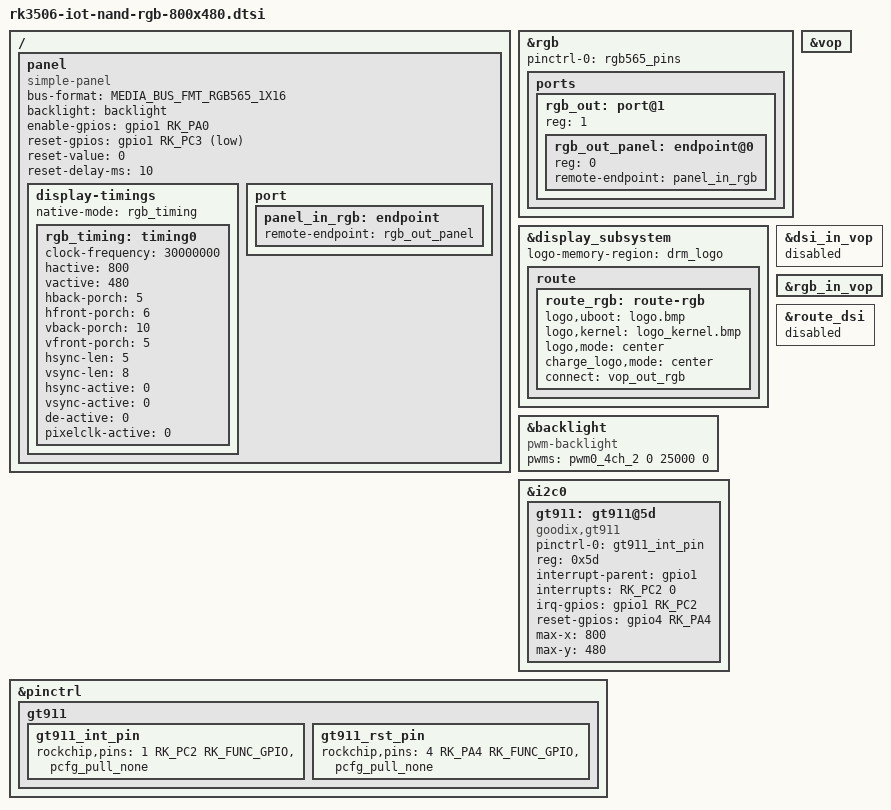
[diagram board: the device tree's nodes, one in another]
// SPDX-License-Identifier: (GPL-2.0+ OR MIT)
/*
 * Copyright (c) 2024 Rockchip Electronics Co., Ltd.
 */

#include <dt-bindings/display/media-bus-format.h>

/ {
	panel: panel {
		compatible = "simple-panel";
		bus-format = <MEDIA_BUS_FMT_RGB565_1X16>;
		backlight = <&backlight>;
		enable-gpios = <&gpio1 RK_PA0 GPIO_ACTIVE_HIGH>;
		//enable-delay-ms = <20>;
		reset-gpios = <&gpio1 RK_PC3 GPIO_ACTIVE_LOW>;
		reset-value = <0>;
		reset-delay-ms = <10>;
		status = "okay";

		display-timings {
			native-mode = <&rgb_timing>;

			rgb_timing: timing0 {
				clock-frequency = <30000000>;
				hactive = <800>;
				vactive = <480>;
				hback-porch = <5>;
				hfront-porch = <6>;
				vback-porch = <10>;
				vfront-porch = <5>;
				hsync-len = <5>;
				vsync-len = <8>;
				hsync-active = <0>;
				vsync-active = <0>;
				de-active = <0>;
				pixelclk-active = <0>;
			};
		};

		port {
			panel_in_rgb: endpoint {
				remote-endpoint = <&rgb_out_panel>;
			};
		};
	};

};

&rgb {
	status = "okay";
	pinctrl-names = "default";
	pinctrl-0 = <&rgb565_pins>;

	ports {
		rgb_out: port@1 {
			reg = <1>;
			#address-cells = <1>;
			#size-cells = <0>;

			rgb_out_panel: endpoint@0 {
				reg = <0>;
				remote-endpoint = <&panel_in_rgb>;
			};
		};
	};
};

&display_subsystem {
	status = "okay";
	logo-memory-region = <&drm_logo>;
	route {
		route_rgb: route-rgb {
			status = "okay";
			logo,uboot = "logo.bmp";
			logo,kernel = "logo_kernel.bmp";
			logo,mode = "center";
			charge_logo,mode = "center";
			connect = <&vop_out_rgb>;
		};
	};
};

&vop {
	status = "okay";
};

&dsi_in_vop {
	status = "disabled";
};

&rgb_in_vop {
	status = "okay";
};

&route_dsi {
	status = "disabled";
};

&route_rgb {
	status = "okay";
};

&backlight {
	compatible = "pwm-backlight";
	pwms = <&pwm0_4ch_2 0 25000 0>;
	status = "okay";
};

// TOUCH
&i2c0 {
	status = "okay";

	gt911: gt911@5d {
		status = "okay";
		pinctrl-names = "default";
		pinctrl-0 = <&gt911_int_pin>;
		compatible = "goodix,gt911";
		reg = <0x5d>;
		interrupt-parent = <&gpio1>;
		interrupts = <RK_PC2 0>;
 
		irq-gpios = <&gpio1 RK_PC2 0>;
		reset-gpios = <&gpio4 RK_PA4 GPIO_ACTIVE_HIGH>;
		max-x = <800>;
		max-y = <480>;
	};
};

&pinctrl {
	gt911{
		gt911_int_pin: gt911_int_pin {
			rockchip,pins = <1 RK_PC2 RK_FUNC_GPIO &pcfg_pull_none>;
		};
		gt911_rst_pin: gt911_rst_pin {
			rockchip,pins = <4 RK_PA4 RK_FUNC_GPIO &pcfg_pull_none>;
		};
	};
};


